# STM32MP157 register map
File version: 1.7
CPU: CM4 r0p1, little endian, no MPU, FPU, 4 interrupt priority bits
Registers are 32-bit, read-write, reset 0x0 unless marked. A register's access mark holds for its fields unless they carry their own. Offsets are from the block's base; [hi:lo] are bit positions; {n}, {i} and the like mark numbered series.

## DSI — DSIHOST1
Base 0x5A000000
0x00 VR ro reset 0x3133312A — DSI Host version register
  [31:0] VERSION
0x04 CR — DSI Host control register
  [0] EN
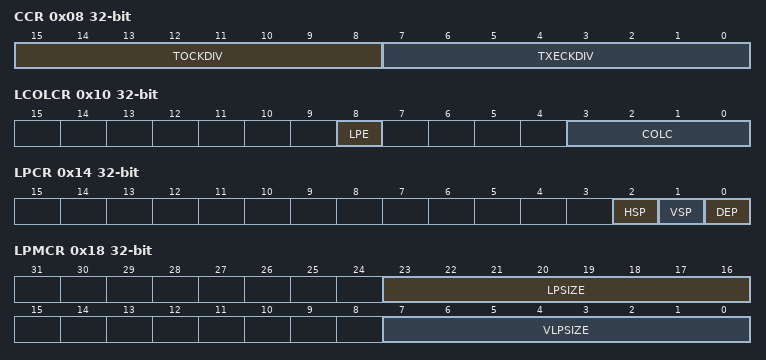
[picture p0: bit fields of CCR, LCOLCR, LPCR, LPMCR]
0x08 CCR — DSI Host clock control register
  [15:8] TOCKDIV, [7:0] TXECKDIV
0x0C LVCIDR — DSI Host LTDC VCID register
  [1:0] VCID
0x10 LCOLCR — DSI Host LTDC color coding register
  [8] LPE, [3:0] COLC
0x14 LPCR — DSI Host LTDC polarity configuration register
  [2] HSP, [1] VSP, [0] DEP
0x18 LPMCR — DSI Host low-power mode configuration register
  [23:16] LPSIZE, [7:0] VLPSIZE
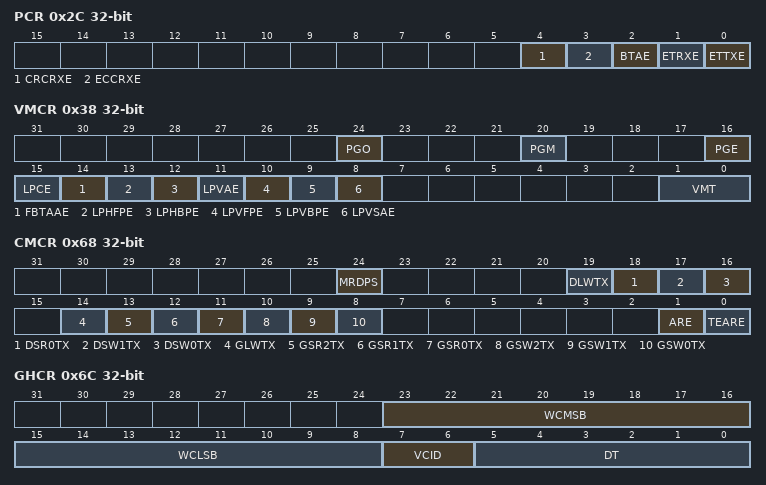
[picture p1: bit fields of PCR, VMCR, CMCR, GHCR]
0x2C PCR — DSI Host protocol configuration register
  [4] CRCRXE, [3] ECCRXE, [2] BTAE, [1] ETRXE, [0] ETTXE
0x30 GVCIDR ro — DSI Host generic VCID register
  [1:0] VCID
0x34 MCR reset 0x1 — DSI Host mode configuration register
  [0] CMDM
0x38 VMCR — DSI Host video mode configuration register
  [24] PGO, [20] PGM, [16] PGE, [15] LPCE, [14] FBTAAE, [13] LPHFPE, [12] LPHBPE, [11] LPVAE, [10] LPVFPE, [9] LPVBPE, [8] LPVSAE, [1:0] VMT
0x3C VPCR — DSI Host video packet configuration register
  [13:0] VPSIZE
0x40 VCCR — DSI Host video chunks configuration register
  [12:0] NUMC
0x44 VNPCR — DSI Host video null packet configuration register
  [12:0] NPSIZE
0x48 VHSACR — DSI Host video HSA configuration register
  [11:0] HSA
0x4C VHBPCR — DSI Host video HBP configuration register
  [11:0] HBP
0x50 VLCR — DSI Host video line configuration register
  [14:0] HLINE
0x54 VVSACR — DSI Host video VSA configuration register
  [9:0] VSA
0x58 VVBPCR — DSI Host video VBP configuration register
  [9:0] VBP
0x5C VVFPCR — DSI Host video VFP configuration register
  [9:0] VFP
0x60 VVACR — DSI Host video VA configuration register
  [13:0] VA
0x64 LCCR — DSI Host LTDC command configuration register
  [15:0] CMDSIZE
0x68 CMCR — DSI Host command mode configuration register
  [24] MRDPS, [19] DLWTX, [18] DSR0TX, [17] DSW1TX, [16] DSW0TX, [14] GLWTX, [13] GSR2TX, [12] GSR1TX, [11] GSR0TX, [10] GSW2TX, [9] GSW1TX, [8] GSW0TX, [1] ARE, [0] TEARE
0x6C GHCR — DSI Host generic header configuration register
  [23:16] WCMSB, [15:8] WCLSB, [7:6] VCID, [5:0] DT
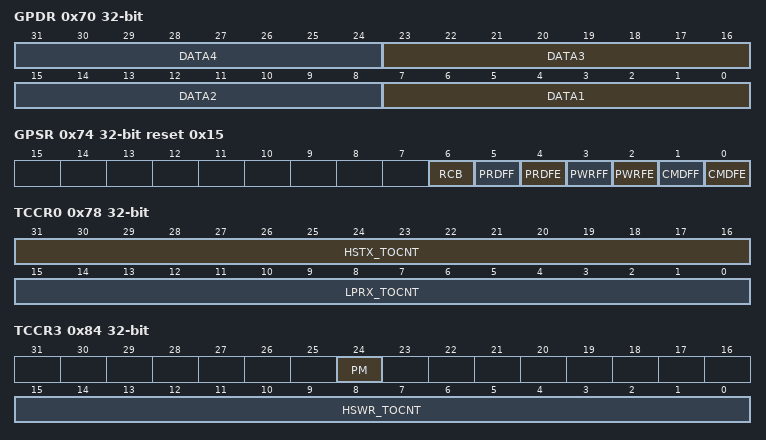
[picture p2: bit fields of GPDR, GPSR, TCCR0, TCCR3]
0x70 GPDR — DSI Host generic payload data register
  [8n-1:8n-8] DATA{n} (n=1..4)
0x74 GPSR ro reset 0x15 — DSI Host generic packet status register
  [6] RCB, [5] PRDFF, [4] PRDFE, [3] PWRFF, [2] PWRFE, [1] CMDFF, [0] CMDFE
0x78 TCCR0 — DSI Host timeout counter configuration register 0
  [31:16] HSTX_TOCNT, [15:0] LPRX_TOCNT
0x7C TCCR1 — DSI Host timeout counter configuration register 1
  [15:0] HSRD_TOCNT
0x80 TCCR2 — DSI Host timeout counter configuration register 2
  [15:0] LPRD_TOCNT
0x84 TCCR3 — DSI Host timeout counter configuration register 3
  [24] PM, [15:0] HSWR_TOCNT
0x88 TCCR4 — DSI Host timeout counter configuration register 4
  [15:0] LPWR_TOCNT
0x8C TCCR5 — DSI Host timeout counter configuration register 5
  [15:0] BTA_TOCNT
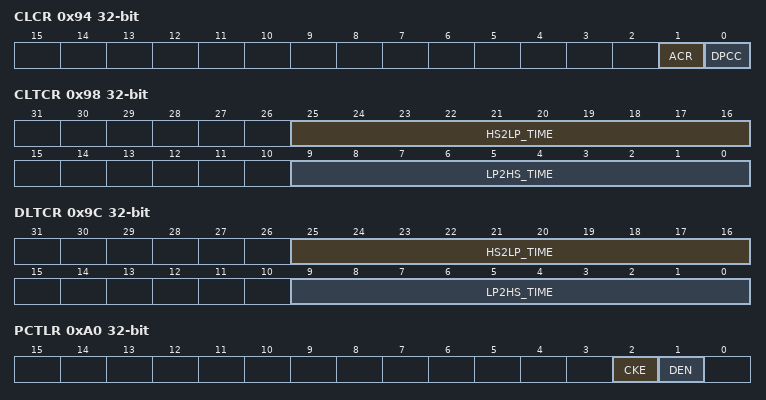
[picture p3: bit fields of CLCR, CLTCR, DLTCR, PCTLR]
0x94 CLCR — DSI Host clock lane configuration register
  [1] ACR, [0] DPCC
0x98 CLTCR — DSI Host clock lane timer configuration register
  [25:16] HS2LP_TIME, [9:0] LP2HS_TIME
0x9C DLTCR — DSI Host data lane timer configuration register
  [25:16] HS2LP_TIME, [9:0] LP2HS_TIME
0xA0 PCTLR — DSI Host PHY control register
  [2] CKE, [1] DEN
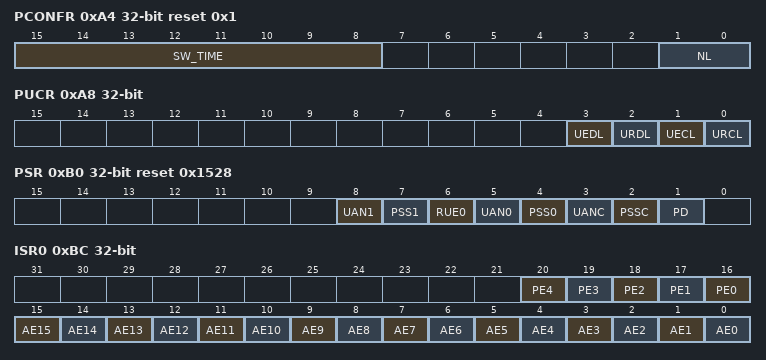
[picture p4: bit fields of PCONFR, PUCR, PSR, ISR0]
0xA4 PCONFR reset 0x1 — DSI Host PHY configuration register
  [15:8] SW_TIME, [1:0] NL
0xA8 PUCR — DSI Host PHY ULPS control register
  [3] UEDL, [2] URDL, [1] UECL, [0] URCL
0xAC PTTCR — DSI Host PHY TX triggers configuration register
  [3:0] TX_TRIG
0xB0 PSR ro reset 0x1528 — DSI Host PHY status register
  [8] UAN1, [7] PSS1, [6] RUE0, [5] UAN0, [4] PSS0, [3] UANC, [2] PSSC, [1] PD
0xBC ISR0 ro — DSI Host interrupt and status register 0
  [n+16] PE{n} (n=0..4) — PHY error {n}
  [n] AE{n} (n=0..15) — Acknowledge error {n}
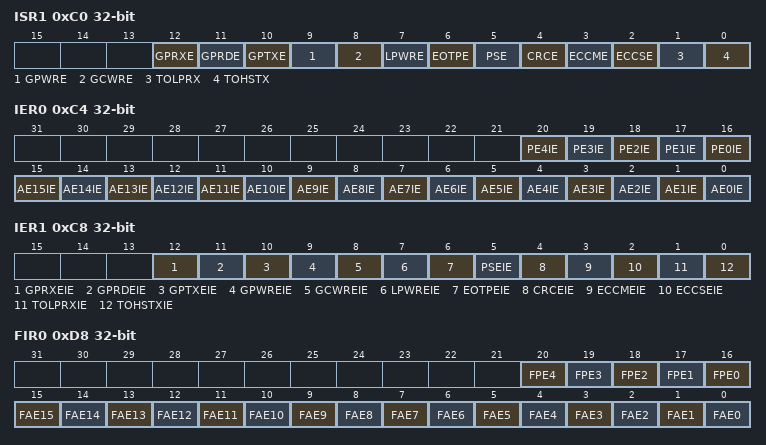
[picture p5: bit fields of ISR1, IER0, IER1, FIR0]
0xC0 ISR1 ro — DSI Host interrupt and status register 1
  [12] GPRXE, [11] GPRDE, [10] GPTXE, [9] GPWRE, [8] GCWRE, [7] LPWRE, [6] EOTPE, [5] PSE, [4] CRCE, [3] ECCME, [2] ECCSE, [1] TOLPRX, [0] TOHSTX
0xC4 IER0 — DSI Host interrupt enable register 0
  [n+16] PE{n}IE (n=0..4) — PHY error {n} interrupt enable
  [n] AE{n}IE (n=0..15) — Acknowledge error {n} interrupt enable
0xC8 IER1 — DSI Host interrupt enable register 1
  [12] GPRXEIE, [11] GPRDEIE, [10] GPTXEIE, [9] GPWREIE, [8] GCWREIE, [7] LPWREIE, [6] EOTPEIE, [5] PSEIE, [4] CRCEIE, [3] ECCMEIE, [2] ECCSEIE, [1] TOLPRXIE, [0] TOHSTXIE
0xD8 FIR0 wo — DSI Host force interrupt register 0
  [n+16] FPE{n} (n=0..4) — Force PHY error {n}
  [n] FAE{n} (n=0..15) — Force acknowledge error {n}
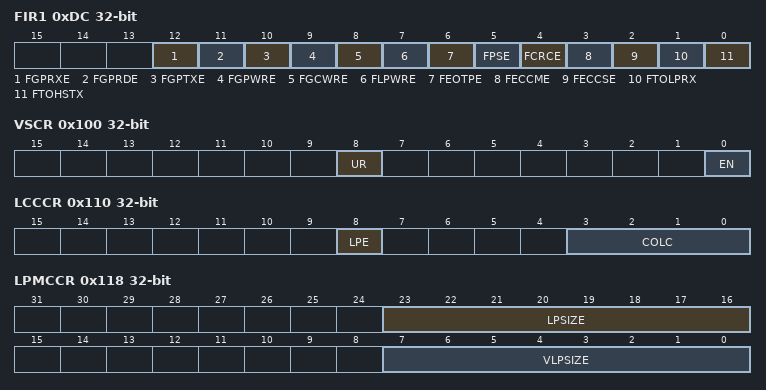
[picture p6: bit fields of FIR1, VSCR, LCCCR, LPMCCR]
0xDC FIR1 wo — DSI Host force interrupt register 1
  [12] FGPRXE, [11] FGPRDE, [10] FGPTXE, [9] FGPWRE, [8] FGCWRE, [7] FLPWRE, [6] FEOTPE, [5] FPSE, [4] FCRCE, [3] FECCME, [2] FECCSE, [1] FTOLPRX, [0] FTOHSTX
0xF4 DLTRCR — DSI Host data lane timer read configuration register
  [14:0] MRD_TIME
0x100 VSCR — DSI Host video shadow control register
  [8] UR, [0] EN
0x10C LCVCIDR — DSI Host LTDC current VCID register
  [1:0] VCID
0x110 LCCCR ro — DSI Host LTDC current color coding register
  [8] LPE, [3:0] COLC
0x118 LPMCCR ro — DSI Host low-power mode current configuration register
  [23:16] LPSIZE, [7:0] VLPSIZE
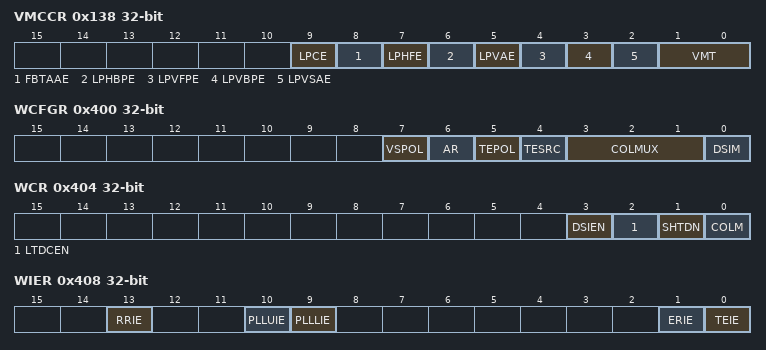
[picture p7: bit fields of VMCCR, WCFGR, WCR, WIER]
0x138 VMCCR ro — DSI Host video mode current configuration register
  [9] LPCE, [8] FBTAAE, [7] LPHFE, [6] LPHBPE, [5] LPVAE, [4] LPVFPE, [3] LPVBPE, [2] LPVSAE, [1:0] VMT
0x13C VPCCR ro — DSI Host video packet current configuration register
  [13:0] VPSIZE
0x140 VCCCR ro — DSI Host video chunks current configuration register
  [12:0] NUMC
0x144 VNPCCR ro — DSI Host video null packet current configuration register
  [12:0] NPSIZE
0x148 VHSACCR ro — DSI Host video HSA current configuration register
  [11:0] HSA
0x14C VHBPCCR ro — DSI Host video HBP current configuration register
  [11:0] HBP
0x150 VLCCR ro — DSI Host video line current configuration register
  [14:0] HLINE
0x154 VVSACCR ro — DSI Host video VSA current configuration register
  [9:0] VSA
0x158 VVBPCCR ro — DSI Host video VBP current configuration register
  [9:0] VBP
0x15C VVFPCCR ro — DSI Host video VFP current configuration register
  [9:0] VFP
0x160 VVACCR ro — DSI Host video VA current configuration register
  [13:0] VA
0x400 WCFGR — DSI wrapper configuration register
  [7] VSPOL, [6] AR, [5] TEPOL, [4] TESRC, [3:1] COLMUX, [0] DSIM
0x404 WCR — DSI wrapper control register
  [3] DSIEN, [2] LTDCEN, [1] SHTDN, [0] COLM
0x408 WIER — DSI wrapper interrupt enable register
  [13] RRIE, [10] PLLUIE, [9] PLLLIE, [1] ERIE, [0] TEIE
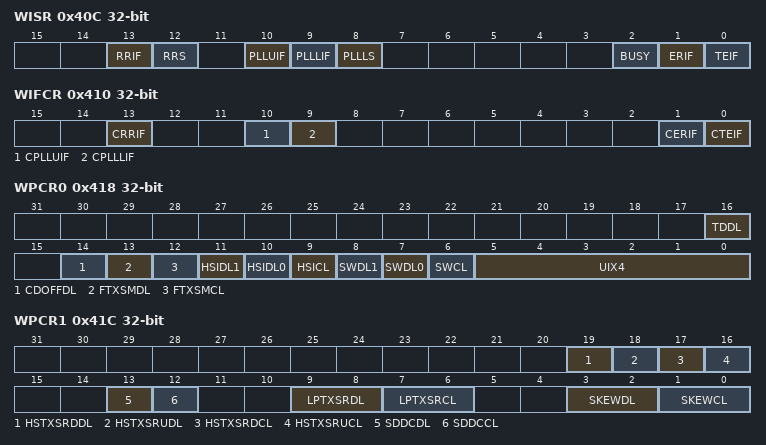
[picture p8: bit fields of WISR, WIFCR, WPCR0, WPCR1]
0x40C WISR ro — DSI wrapper interrupt and status register
  [13] RRIF, [12] RRS, [10] PLLUIF, [9] PLLLIF, [8] PLLLS, [2] BUSY, [1] ERIF, [0] TEIF
0x410 WIFCR wo — DSI wrapper interrupt flag clear register
  [13] CRRIF, [10] CPLLUIF, [9] CPLLLIF, [1] CERIF, [0] CTEIF
0x418 WPCR0 — DSI wrapper PHY configuration register 0
  [16] TDDL, [14] CDOFFDL, [13] FTXSMDL, [12] FTXSMCL, [11] HSIDL1, [10] HSIDL0, [9] HSICL, [8] SWDL1, [7] SWDL0, [6] SWCL, [5:0] UIX4
0x41C WPCR1 — This register shall be programmed only when DSI is stopped (CR. DSIEN=0 and CR.EN = 0).
  [19] HSTXSRDDL, [18] HSTXSRUDL, [17] HSTXSRDCL, [16] HSTXSRUCL, [13] SDDCDL, [12] SDDCCL, [9:8] LPTXSRDL, [7:6] LPTXSRCL, [3:2] SKEWDL, [1:0] SKEWCL
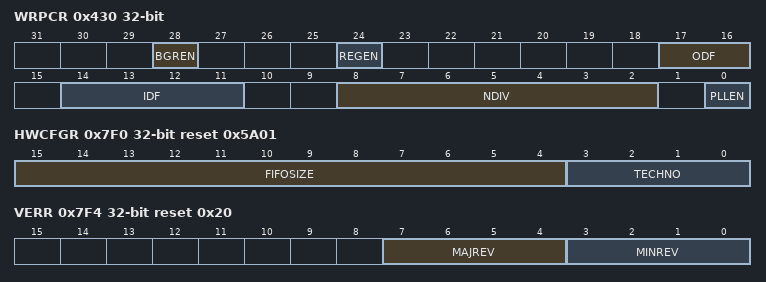
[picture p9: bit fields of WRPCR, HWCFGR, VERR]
0x430 WRPCR — DSI wrapper regulator and PLL control register
  [28] BGREN, [24] REGEN, [17:16] ODF, [14:11] IDF, [8:2] NDIV, [0] PLLEN
0x7F0 HWCFGR ro reset 0x5A01 — DSI Host hardware configuration register
  [15:4] FIFOSIZE, [3:0] TECHNO
0x7F4 VERR ro reset 0x20 — DSI Host version register
  [7:4] MAJREV, [3:0] MINREV
0x7F8 IPIDR ro reset 0x160071 — DSI Host identification register
  [31:0] ID
0x7FC SIDR ro reset 0xA3C5DD02 — DSI Host size identification register
  [31:0] SID
